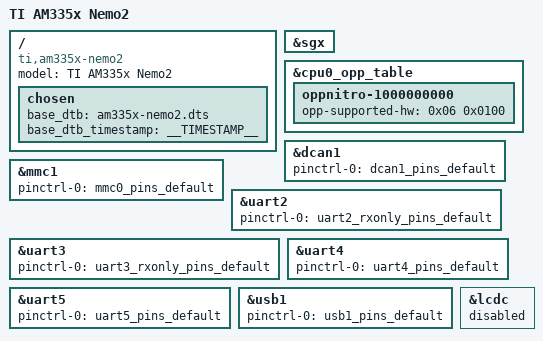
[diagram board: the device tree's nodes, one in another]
// SPDX-License-Identifier: GPL-2.0-only
/*
 * Copyright (C) 2012 Texas Instruments Incorporated - http://www.ti.com/
 */
/dts-v1/;

#include "am33xx.dtsi"
#include "am335x-bone-common.dtsi"
#include "am335x-boneblack-common.dtsi"
#include "am335x-nemo2-common.dtsi"

/* #include "am335x-bone-jtag.dtsi" */

/ {
	model = "TI AM335x Nemo2";
	compatible = "ti,am335x-nemo2", "ti,am335x-bone-black", "ti,am335x-bone", "ti,am33xx";

	chosen {
		base_dtb = "am335x-nemo2.dts";
		base_dtb_timestamp = __TIMESTAMP__;
	};
};

&sgx {
	status = "okay";
};

&cpu0_opp_table {
	/*
	 * All PG 2.0 silicon may not support 1GHz but some of the early
	 * BeagleBone Blacks have PG 2.0 silicon which is guaranteed
	 * to support 1GHz OPP so enable it for PG 2.0 on this board.
	 */
	oppnitro-1000000000 {
		opp-supported-hw = <0x06 0x0100>;
	};
};

&dcan1 {
	status = "okay";
	pinctrl-names = "default";
	pinctrl-0 = <&dcan1_pins_default>;
};

&mmc1 {
	status = "okay";
	pinctrl-names = "default";
	pinctrl-0 = <&mmc0_pins_default>;   /* NOTE mmc0 vs mmc1 naming difference - by design. */
};

&uart2 {
	status = "okay";
	pinctrl-names = "default";
	pinctrl-0 = <&uart2_rxonly_pins_default>;   /* NOTE: Receive only port */
};

&uart3 {
	status = "okay";
	pinctrl-names = "default";
	pinctrl-0 = <&uart3_rxonly_pins_default>;   /* NOTE: Receive only port */
};

&uart4 {
	status = "okay";
	pinctrl-names = "default";
	pinctrl-0 = <&uart4_pins_default>;
};

&uart5 {
	status = "okay";
	pinctrl-names = "default";
	pinctrl-0 = <&uart5_pins_default>;
};

&usb1 {
	status = "okay";
	pinctrl-names = "default";
	pinctrl-0 = <&usb1_pins_default>;
};

/* IS THIS NECESSARY?
&rtc {
	status = "okay";
	pinctrl-names = "default";
	pinctrl-0 = <&rtc_pins_default>;
};
*/

&lcdc {
	status = "disabled";
};
